# PIC18F56Q43 register map
Vendor: Microchip
Registers are 8-bit, read-write, reset 0x0 unless marked. A register's access mark holds for its fields unless they carry their own. Addresses are absolute, and some are shared; only a register's first bit layout is shown; [hi:lo] are bit positions; {n}, {i} and the like mark numbered series.

## pad
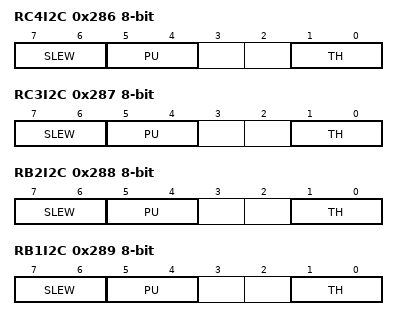
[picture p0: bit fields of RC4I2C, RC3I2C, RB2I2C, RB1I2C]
0x286 RC4I2C
  [7:6] SLEW, [5:4] PU, [1:0] TH
0x287 RC3I2C
  [7:6] SLEW, [5:4] PU, [1:0] TH
0x288 RB2I2C
  [7:6] SLEW, [5:4] PU, [1:0] TH
0x289 RB1I2C
  [7:6] SLEW, [5:4] PU, [1:0] TH

## i2c
0x28B I2C1RXB ro reset not defined — I2C RECEIVE BUFFER REGISTER (power-on value xxxxxxxx)
  [7:0] RXB
0x28C I2C1TXB wo reset not defined — I2C TRANSMIT BUFFER REGISTER (power-on value xxxxxxxx)
  [7:0] TXB
0x28D I2C1CNT reset not defined — I2C COUNT REGISTER (power-on value xxxxxxxx)
  [7:0] CNT
0x28E I2C1ADB0 reset not defined — I2C ADDRESS BUFFER REGISTER 0 (power-on value xxxxxxxx)
  [7:0] ADB
0x28F I2C1ADB1 reset not defined — I2C ADDRESS BUFFER REGISTER 1 (power-on value xxxxxxxx)
  [7:0] ADB
0x290 I2C1ADR0 reset 0xFF — I2C ADDRESS REGISTER 0
  [7:0] ADR
0x291 I2C1ADR1 reset 0xFE — I2C ADDRESS REGISTER 1
  [7:1] ADR
0x292 I2C1ADR2 reset 0xFF — I2C ADDRESS REGISTER 2
  [7:0] ADR
0x293 I2C1ADR3 reset 0xFE — I2C ADDRESS REGISTER 3
  [7:1] ADR
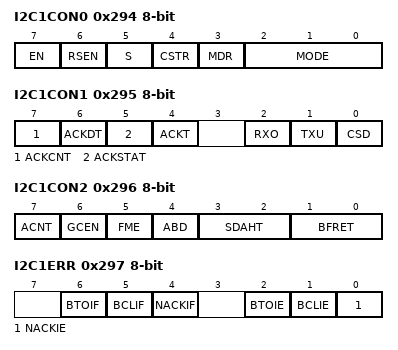
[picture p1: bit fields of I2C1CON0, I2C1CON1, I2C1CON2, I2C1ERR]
0x294 I2C1CON0 — I2C CONTROL REGISTER 0
  [7] EN
  [6] RSEN
  [5] S — (can only be set)
  [4] CSTR — (can only be cleared)
  [3] MDR ro
  [2:0] MODE
0x295 I2C1CON1 — I2C CONTROL REGISTER 1
  [7] ACKCNT, [6] ACKDT, [5] ACKSTAT, [4] ACKT ro, [2] RXO, [1] TXU, [0] CSD
0x296 I2C1CON2 — I2C CONTROL REGISTER 2
  [7] ACNT, [6] GCEN, [5] FME, [4] ABD, [3:2] SDAHT, [1:0] BFRET
0x297 I2C1ERR — I2C ERROR REGISTER
  [6] BTOIF, [5] BCLIF, [4] NACKIF, [2] BTOIE, [1] BCLIE, [0] NACKIE
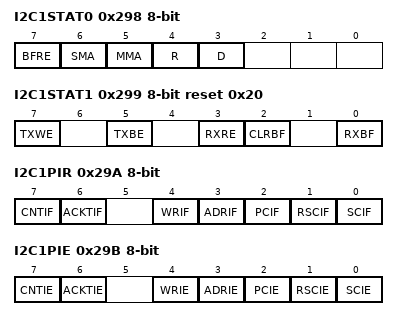
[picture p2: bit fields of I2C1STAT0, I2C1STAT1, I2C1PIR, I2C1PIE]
0x298 I2C1STAT0 ro — I2C STATUS REGISTER 0
  [7] BFRE
  [6] SMA
  [5] MMA
  [4] R — Read/Write Information bit
  [3] D — Data/Address bit
0x299 I2C1STAT1 reset 0x20 — I2C STATUS REGISTER 1
  [7] TXWE
  [5] TXBE ro
  [3] RXRE
  [2] CLRBF — (can only be set)
  [0] RXBF ro
0x29A I2C1PIR — I2C PERIPHERAL INTERRUPT FLAG REGISTER
  [7] CNTIF, [6] ACKTIF, [4] WRIF, [3] ADRIF, [2] PCIF, [1] RSCIF, [0] SCIF
0x29B I2C1PIE — I2C PERIPHERAL INTERRUPT ENABLE REGISTER
  [7] CNTIE, [6] ACKTIE, [4] WRIE, [3] ADRIE, [2] PCIE, [1] RSCIE, [0] SCIE
0x29C I2C1CLK — I2C CLOCK SELECTION REGISTER
  [4:0] CLK
0x29D I2C1BTO — I2C BUS TIME OUT SELECTION REGISTER
  [3:0] BTO

## uart_protocol
{0x28E+0x13*i} U{i}RXB ro (i=1..5)
  [7:0] RXB
0x2A2 U1RXCHK
  [7:0] RXCHK
{0x290+0x13*i} U{i}TXB (i=1..5)
  [7:0] TXB
0x2A4 U1TXCHK
  [7:0] TXCHK
{0x292+0x13*i} U{i}P1L (i=1..5)
  [7:0] P1L
{0x2A4+2i} U1P{i}H (i=1..3)
  [0] P{i}H
{0x294+0x13*i} U{i}P2L (i=1..5)
  [7:0] P2L
{0x296+0x13*i} U{i}P3L reset not defined (i=1..5) — (power-on value xxxxxxxx)
  [7:0] P3L
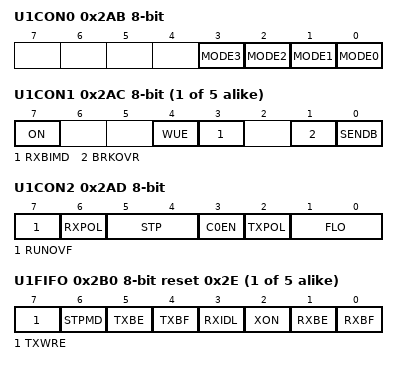
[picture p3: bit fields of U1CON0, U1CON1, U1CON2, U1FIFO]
0x2AB U1CON0
  [n] MODE{n} (n=0..3)
{0x299+0x13*i} U{i}CON1 (i=1..5)
  [7] ON, [4] WUE, [3] RXBIMD, [1] BRKOVR, [0] SENDB
0x2AD U1CON2
  [7] RUNOVF, [6] RXPOL, [5:4] STP, [3] C0EN, [2] TXPOL, [1:0] FLO
{0x29B+0x13*i} U{i}BRGL (i=1..5)
  [7:0] BRGL
{0x29C+0x13*i} U{i}BRGH (i=1..5)
  [7:0] BRGH
{0x29D+0x13*i} U{i}FIFO reset 0x2E (i=1..5)
  [7] TXWRE, [6] STPMD, [5] TXBE, [4] TXBF ro, [3] RXIDL ro, [2] XON ro, [1] RXBE ro, [0] RXBF ro
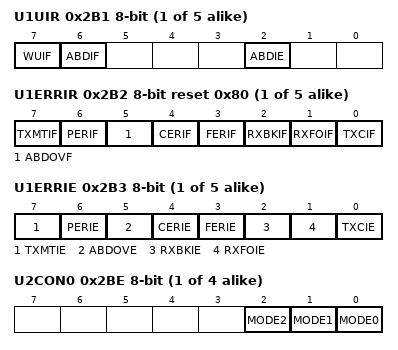
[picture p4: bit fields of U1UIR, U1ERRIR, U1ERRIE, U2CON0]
{0x29E+0x13*i} U{i}UIR (i=1..5)
  [7] WUIF, [6] ABDIF, [2] ABDIE
{0x29F+0x13*i} U{i}ERRIR reset 0x80 (i=1..5)
  [7] TXMTIF, [6] PERIF, [5] ABDOVF, [4] CERIF, [3] FERIF, [2] RXBKIF, [1] RXFOIF, [0] TXCIF
{0x2A0+0x13*i} U{i}ERRIE (i=1..5)
  [7] TXMTIE, [6] PERIE, [5] ABDOVE, [4] CERIE, [3] FERIE, [2] RXBKIE, [1] RXFOIE, [0] TXCIE
{0x298+0x13*i} U{i}CON0 (i=2..5)
  [2] MODE2, [1] MODE1, [0] MODE0
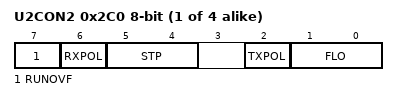
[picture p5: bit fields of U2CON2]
{0x29A+0x13*i} U{i}CON2 (i=2..5)
  [7] RUNOVF, [6] RXPOL, [5:4] STP, [2] TXPOL, [1:0] FLO

## tmr_smt
0x300 SMT1TMRL
  [7:0] SMT1TMR
0x301 SMT1TMRH
  [7:0] SMT1TMR
0x302 SMT1TMRU
  [7:0] SMT1TMR
0x303 SMT1CPRL ro reset not defined — (power-on value xxxxxxxx)
  [7:0] SMT1CPR
0x304 SMT1CPRH ro reset not defined — (power-on value xxxxxxxx)
  [7:0] SMT1CPR
0x305 SMT1CPRU ro reset not defined — (power-on value xxxxxxxx)
  [7:0] SMT1CPR
0x306 SMT1CPWL ro reset not defined — (power-on value xxxxxxxx)
  [7:0] SMT1CPW
0x307 SMT1CPWH ro reset not defined — (power-on value xxxxxxxx)
  [7:0] SMT1CPW
0x308 SMT1CPWU ro reset not defined — (power-on value xxxxxxxx)
  [7:0] SMT1CPW
0x309 SMT1PRL reset 0xFF
  [7:0] SMT1PR
0x30A SMT1PRH reset 0xFF
  [7:0] SMT1PR
0x30B SMT1PRU reset 0xFF
  [7:0] SMT1PR
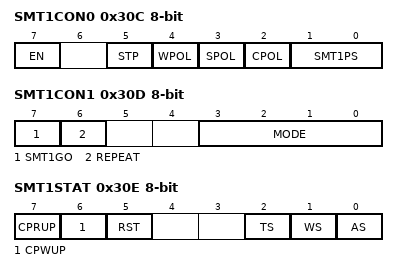
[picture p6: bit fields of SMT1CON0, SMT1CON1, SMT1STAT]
0x30C SMT1CON0
  [7] EN, [5] STP, [4] WPOL, [3] SPOL, [2] CPOL, [1:0] SMT1PS
0x30D SMT1CON1
  [7] SMT1GO, [6] REPEAT, [3:0] MODE
0x30E SMT1STAT
  [7] CPRUP, [6] CPWUP, [5] RST, [2] TS ro, [1] WS ro, [0] AS ro
0x30F SMT1CLK
  [3:0] CSEL
0x310 SMT1SIG
  [5:0] SSEL
0x311 SMT1WIN
  [5:0] WSEL
